# CORE_PRM register map
Vendor: Texas Instruments
Peripheral module from a debugger description file (folder am572x).
Registers are 32-bit, access per field, reset 0x0 unless marked. A register's access mark holds for its fields unless they carry their own. Offsets are as the file gives them; lines under a group give offsets from that group; [hi:lo] are bit positions; {n}, {i} and the like mark numbered series; 'fields as' and 'values as' point back to an identical list; <NAME> marks a mode.

## CORE_PRM
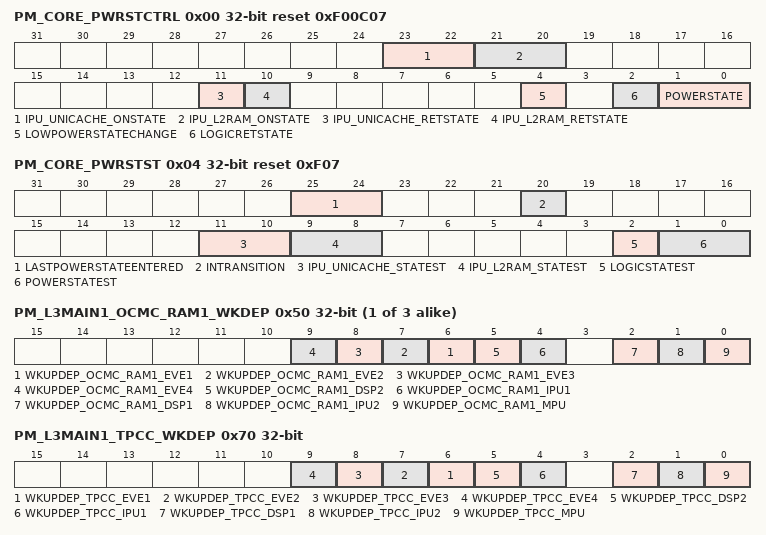
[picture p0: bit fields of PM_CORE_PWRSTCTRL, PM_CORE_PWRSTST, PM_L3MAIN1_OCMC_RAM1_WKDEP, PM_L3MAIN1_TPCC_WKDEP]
0x00 PM_CORE_PWRSTCTRL reset 0xF00C07 — This register controls the CORE power state to reach upon a domain sleep transition
  [23:22] IPU_UNICACHE_ONSTATE ro — IPU UNICACHE bank state when domain is ON.
    3=MEM_ON (Memory bank is on when the domain is ON.)
  [21:20] IPU_L2RAM_ONSTATE ro — IPU L2 bank state when domain is ON.
    3=MEM_ON (Memory bank is on when the domain is ON.)
  [11] IPU_UNICACHE_RETSTATE rw — IPU UNICACHE bank state when domain is RETENTION.
    0=MEM_OFF (Memory bank is off when the domain is in the RETENTION state.); 1=MEM_RET (Memory bank is retained when domain is in RETENTION state.)
  [10] IPU_L2RAM_RETSTATE rw — IPU L2 bank state when domain is RETENTION.
    values as IPU_UNICACHE_RETSTATE
  [4] LOWPOWERSTATECHANGE rw — Power state change request when domain has already performed a sleep transition. Allows going into deeper low power state without waking up the power domain.
    0=DIS (Do not request a low power state change.); 1=EN (Request a low power state change. This bit is automatically cleared when the power state is effectively changed or when power state is ON.)
  [2] LOGICRETSTATE rw — Logic state when power domain is RETENTION
    0=LOGIC_OFF (Only retention registers are retained and remaing logic is off when the domain is in RETENTION state.); 1=LOGIC_RET (Whole logic is retained when domain is in RETENTION state.)
  [1:0] POWERSTATE rw — Power state control
    1=RET (RETENTION state); 2=INACT (INACTIVE state); 3=ON (ON State)
0x04 PM_CORE_PWRSTST reset 0xF07 — This register provides a status on the current CORE power domain state. [warm reset insensitive]
  [25:24] LASTPOWERSTATEENTERED rw — Last low power state entered. Set to 0x3 upon write of the same only. This register is intended for debug purpose only.
    0=OFF (Power domain was previously OFF); 1=RET (Power domain was previously in RETENTION); 2=INACTIVE (Power domain was previously ON-INACTIVE); 3=ON (Power domain was previously ON-ACTIVE)
  [20] INTRANSITION ro — Domain transition status
    0=NO (No on-going transition on power domain); 1=ONGOING (Power domain transition is in progress.)
  [11:10] IPU_UNICACHE_STATEST ro — IPU UNICACHE bank state status
    0=MEM_OFF (Memory is OFF); 1=MEM_RET (Memory is RETENTION); 3=MEM_ON (Memory is ON)
  [9:8] IPU_L2RAM_STATEST ro — IPU L2 bank state status
    values as IPU_UNICACHE_STATEST
  [2] LOGICSTATEST ro — Logic state status
    0=OFF (Logic in domain is OFF); 1=ON (Logic in domain is ON)
  [1:0] POWERSTATEST ro — Current power state status
    1=RET (Power domain is in RETENTION); 2=INACTIVE (Power domain is ON-INACTIVE); 3=ON (Power domain is ON-ACTIVE)
{0x48+8i} PM_L3MAIN1_OCMC_RAM{i}_WKDEP (i=1..3) — This register controls wakeup dependency based on OCMC_RAM{i} service requests.
  [all] fields
    0=DISABLED (Dependency is disabled); 1=ENABLED (Dependency is enabled)
  [n+5] WKUPDEP_OCMC_RAM{i}_EVE{n} rw (n=1..4) — Wakeup dependency from OCMC_RAM{i} module (SWakeup signal) towards EVE{n} + L3_MAIN1 + L4PER1 + L4PER2 + L4PER3 domains
  [5] WKUPDEP_OCMC_RAM{i}_DSP2 rw — Wakeup dependency from OCMC_RAM{i} module (SWakeup signal) towards DSP2 + L3_MAIN1 + L4PER1 + L4PER2 + L4PER3 domains
  [4] WKUPDEP_OCMC_RAM{i}_IPU1 rw — Wakeup dependency from OCMC_RAM{i} module (SWakeup signal) towards IPU1 + L3_MAIN1 + L4PER1 + L4PER2 + L4PER3 domains
  [2] WKUPDEP_OCMC_RAM{i}_DSP1 rw — Wakeup dependency from OCMC_RAM{i} module (SWakeup signal) towards DSP + L3MAIN1 + L4PER1 + L4PER2 + L4PER3 domains
  [1] WKUPDEP_OCMC_RAM{i}_IPU2 rw — Wakeup dependency from OCMC_RAM{i} module (SWakeup signal) towards IPU2 + L3_MAIN1 + L4PER1 + L4PER2 + L4PER3 domains
  [0] WKUPDEP_OCMC_RAM{i}_MPU rw — Wakeup dependency from OCMC_RAM{i} module (SWakeup signal) towards MPU + L3_MAIN1 + L4PER1 + L4PER2 + L4PER3 domains
0x70 PM_L3MAIN1_TPCC_WKDEP — This register controls wakeup dependency based on TPCC service requests.
  [all] fields
    values as the fields of PM_L3MAIN1_OCMC_RAM1_WKDEP
  [n+5] WKUPDEP_TPCC_EVE{n} rw (n=1..4) — Wakeup dependency from TPCC module (SWakeup signal) towards EVE{n} + L3_MAIN1 + L4PER1 + L4PER2 + L4PER3 domains
  [5] WKUPDEP_TPCC_DSP2 rw — Wakeup dependency from TPCC module (SWakeup signal) towards DSP2 + L3_MAIN1 + L4PER1 + L4PER2 + L4PER3 domains
  [4] WKUPDEP_TPCC_IPU1 rw — Wakeup dependency from TPCC module (SWakeup signal) towards IPU1 + L3_MAIN1 + L4PER1 + L4PER2 + L4PER3 domains
  [2] WKUPDEP_TPCC_DSP1 rw — Wakeup dependency from TPCC module (SWakeup signal) towards DSP + L3MAIN1 + L4PER1 + L4PER2 + L4PER3 domains
  [1] WKUPDEP_TPCC_IPU2 rw — Wakeup dependency from TPCC module (SWakeup signal) towards IPU2 + L3_MAIN1 + L4PER1 + L4PER2 + L4PER3 domains
  [0] WKUPDEP_TPCC_MPU rw — Wakeup dependency from TPCC module (SWakeup signal) towards MPU + L3_MAIN1 + L4PER1 + L4PER2 + L4PER3 domains
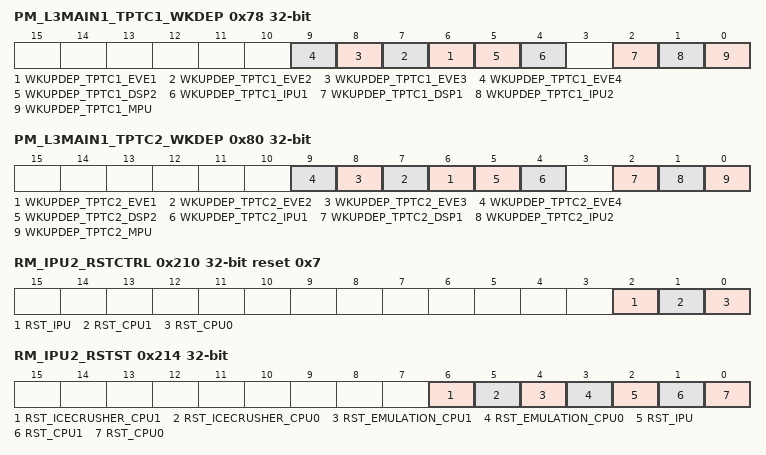
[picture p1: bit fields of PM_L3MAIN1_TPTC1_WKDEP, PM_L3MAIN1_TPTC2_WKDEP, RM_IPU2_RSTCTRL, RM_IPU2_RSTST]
0x78 PM_L3MAIN1_TPTC1_WKDEP — This register controls wakeup dependency based on TPTC service requests.
  [all] fields
    values as the fields of PM_L3MAIN1_OCMC_RAM1_WKDEP
  [n+5] WKUPDEP_TPTC1_EVE{n} rw (n=1..4) — Wakeup dependency from TPTC module (SWakeup signal) towards EVE{n} + L3_MAIN1 + L4PER1 + L4PER2 + L4PER3 domains
  [5] WKUPDEP_TPTC1_DSP2 rw — Wakeup dependency from TPTC module (SWakeup signal) towards DSP2 + L3_MAIN1 + L4PER1 + L4PER2 + L4PER3 domains
  [4] WKUPDEP_TPTC1_IPU1 rw — Wakeup dependency from TPTC module (SWakeup signal) towards IPU1 + L3_MAIN1 + L4PER1 + L4PER2 + L4PER3 domains
  [2] WKUPDEP_TPTC1_DSP1 rw — Wakeup dependency from TPTC module (SWakeup signal) towards DSP + L3MAIN1 + L4PER1 + L4PER2 + L4PER3 domains
  [1] WKUPDEP_TPTC1_IPU2 rw — Wakeup dependency from TPTC module (SWakeup signal) towards IPU2 + L3_MAIN1 + L4PER1 + L4PER2 + L4PER3 domains
  [0] WKUPDEP_TPTC1_MPU rw — Wakeup dependency from TPTC module (SWakeup signal) towards MPU + L3_MAIN1 + L4PER1 + L4PER2 + L4PER3 domains
0x80 PM_L3MAIN1_TPTC2_WKDEP — This register controls wakeup dependency based on TPTC service requests.
  [all] fields
    values as the fields of PM_L3MAIN1_OCMC_RAM1_WKDEP
  [n+5] WKUPDEP_TPTC2_EVE{n} rw (n=1..4) — Wakeup dependency from TPTC module (SWakeup signal) towards EVE{n} + L3_MAIN1 + L4PER1 + L4PER2 + L4PER3 domains
  [5] WKUPDEP_TPTC2_DSP2 rw — Wakeup dependency from TPTC module (SWakeup signal) towards DSP2 + L3_MAIN1 + L4PER1 + L4PER2 + L4PER3 domains
  [4] WKUPDEP_TPTC2_IPU1 rw — Wakeup dependency from TPTC module (SWakeup signal) towards IPU1 + L3_MAIN1 + L4PER1 + L4PER2 + L4PER3 domains
  [2] WKUPDEP_TPTC2_DSP1 rw — Wakeup dependency from TPTC module (SWakeup signal) towards DSP + L3MAIN1 + L4PER1 + L4PER2 + L4PER3 domains
  [1] WKUPDEP_TPTC2_IPU2 rw — Wakeup dependency from TPTC module (SWakeup signal) towards IPU2 + L3_MAIN1 + L4PER1 + L4PER2 + L4PER3 domains
  [0] WKUPDEP_TPTC2_MPU rw — Wakeup dependency from TPTC module (SWakeup signal) towards MPU + L3_MAIN1 + L4PER1 + L4PER2 + L4PER3 domains
0x210 RM_IPU2_RSTCTRL reset 0x7 — This register controls the release of the IPU2 sub-system resets.
  [2] RST_IPU rw — IPU system reset control.
    0=CLEAR (Reset is cleared for IPU CACHE MMU); 1=ASSERT (Reset is asserted for the IPU CACHE MMU)
  [1] RST_CPU1 rw — IPU Cortex M4 CPU1 reset control
    0=CLEAR (Reset is cleared for the IPU Cortex M4 CPU1); 1=ASSERT (Reset is asserted for the IPU Cortex M4 CPU1)
  [0] RST_CPU0 rw — IPU Cortex M4 CPU0 reset control.
    0=CLEAR (Reset is cleared for the IPU Cortex M4 CPU0); 1=ASSERT (Reset is asserted for the IPU Cortex M4 CPU0)
0x214 RM_IPU2_RSTST — This register logs the different reset sources of the IPU2 SS. Each bit is set upon release of the domain reset signal. Must be cleared by software. [warm reset insensitive]
  [6] RST_ICECRUSHER_CPU1 rw — Cortex M4 CPU1 has been reset due to IPU ICECRUSHER1 reset source
    0=RESET_NO (No icecrusher reset); 1=RESET_YES (CPU1 has been reset upon icecrusher reset)
  [5] RST_ICECRUSHER_CPU0 rw — Cortex M4 CPU0 has been reset due to IPU ICECRUSHER0 reset source
    0=RESET_NO (No icecrusher reset); 1=RESET_YES (CPU0 has been reset upon icecrusher reset)
  [4] RST_EMULATION_CPU1 rw — Cortex M4 CPU1 has been reset due to emulation reset source, for example, assert reset command initiated by the icepick module
    0=RESET_NO (No emulation reset); 1=RESET_YES (CPU1 has been reset upon emulation reset)
  [3] RST_EMULATION_CPU0 rw — Cortex M4 CPU0 has been reset due to emulation reset source, for example, assert reset command initiated by the icepick module
    0=RESET_NO (No emulation reset); 1=RESET_YES (CPU0 has been reset upon emulation reset)
  [2] RST_IPU rw — IPU system software reset status
    0=RESET_NO (No software reset occurred); 1=RESET_YES (IPU MMU and CACHE interface has been reset upon software reset)
  [1] RST_CPU1 rw — IPU Cortex-M4 CPU1 software reset status
    0=RESET_NO (No software reset occurred); 1=RESET_YES (Cortex M4 CPU1 has been reset upon software reset)
  [0] RST_CPU0 rw — IPU Cortex-M4 CPU0 software reset status
    0=RESET_NO (No software reset occurred); 1=RESET_YES (Cortex M4 CPU0 has been reset upon software reset)
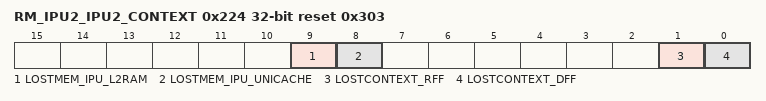
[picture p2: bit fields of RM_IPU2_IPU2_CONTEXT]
0x224 RM_IPU2_IPU2_CONTEXT reset 0x303 — This register contains dedicated IPU2 context statuses. [warm reset insensitive]
  [all] fields
    0=MAINTAINED (Context has been maintained); 1=LOST (Context has been lost)
  [9] LOSTMEM_IPU_L2RAM rw — Specify if memory-based context in IPU_L2RAM memory bank has been lost due to a previous power transition or other reset source.
  [8] LOSTMEM_IPU_UNICACHE rw — Specify if memory-based context in IPU_UNICACHE memory bank has been lost due to a previous power transition or other reset source.
  [1] LOSTCONTEXT_RFF rw — Specify if RFF-based context has been lost due to a previous power transition or other reset source. (set upon assertion of IPU_RET_RST signal)
  [0] LOSTCONTEXT_DFF rw — Specify if DFF-based context has been lost due to a previous power transition or other reset source. (set upon assertion of IPU_RST signal)
